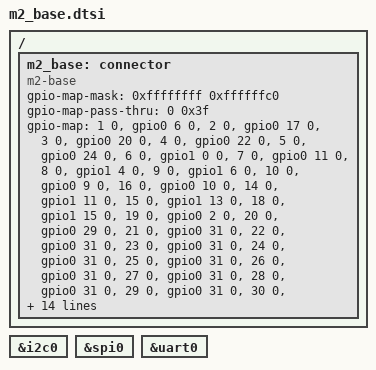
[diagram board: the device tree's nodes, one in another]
/ {
	m2_base: connector {
		compatible = "m2-base";
		#gpio-cells = <2>;
		gpio-map-mask = <0xffffffff 0xffffffc0>;
		gpio-map-pass-thru = <0 0x3f>;
		gpio-map
			= <1  0 &gpio0 6 0>	
			, <2  0 &gpio0 17 0>	
			, <3  0 &gpio0 20 0>	
			, <4  0 &gpio0 22 0>	
			, <5  0 &gpio0 24 0>	
			, <6  0 &gpio1 0 0>	
			, <7  0 &gpio0 11 0>	
			, <8  0 &gpio1 4 0>	
			, <9  0 &gpio1 6 0>	
			, <10 0 &gpio0 9 0>	
			, <16 0 &gpio0 10 0>
			, <14 0 &gpio1 11 0>
			, <15 0 &gpio1 13 0>
			, <18 0 &gpio1 15 0>
			, <19 0 &gpio0 2 0>	
			, <20 0 &gpio0 29 0>
			, <21 0 &gpio0 31 0>
			, <22 0 &gpio0 31 0>
			, <23 0 &gpio0 31 0>
			, <24 0 &gpio0 31 0>
			, <25 0 &gpio0 31 0>
			, <26 0 &gpio0 31 0>
			, <27 0 &gpio0 31 0>
			, <28 0 &gpio0 31 0>
			, <29 0 &gpio0 31 0>
			, <30 0 &gpio0 31 0>
			, <31 0 &gpio0 31 0>
			, <31 0 &gpio0 31 0>
			, <31 0 &gpio0 31 0>
			, <31 0 &gpio0 31 0>
			, <31 0 &gpio0 31 0>
			, <31 0 &gpio0 31 0>
			, <31 0 &gpio0 31 0>
			, <31 0 &gpio0 31 0>
			, <31 0 &gpio0 31 0>
			, <40 0 &gpio0 31 0>
			, <40 0 &gpio0 31 0>
			, <40 0 &gpio0 31 0>
			, <40 0 &gpio0 31 0>
			, <40 0 &gpio0 31 0>
			, <40 0 &gpio0 31 0>
			, <40 0 &gpio0 31 0>
			, <40 0 &gpio0 31 0>
			, <40 0 &gpio0 31 0>
			, <40 0 &gpio0 31 0>
			, <40 0 &gpio0 31 0>
			, <40 0 &gpio0 31 0>
			, <40 0 &gpio0 31 0>
			, <40 0 &gpio0 31 0>
			, <40 0 &gpio0 31 0>
			, <40 0 &gpio0 31 0>
			, <40 0 &gpio0 31 0>
			, <40 0 &gpio0 31 0>

			;
	};
};

m2_base_i2c: &i2c0 {};
m2_base_spi: &spi0 {};
m2_base_serial: &uart0 {};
